# STM32F0x8 register map
File version: 1.3
CPU: CM0 r0p0, little endian, no MPU, no FPU, 2 interrupt priority bits
Registers are 32-bit, read-write, reset 0x0 unless marked. A register's access mark holds for its fields unless they carry their own. Offsets are from the block's base; [hi:lo] are bit positions; 'fields as' and 'values as' point back to an identical list.

## COMP — General purpose comparators
Base 0x40010000
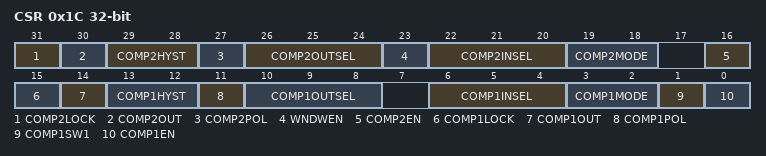
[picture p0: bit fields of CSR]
0x1C CSR access per field — control and status register
  [31] COMP2LOCK rw — Comparator 2 lock
    0=Unlocked (Comparator 2 CSR bits (CSR[31:16]) are read-write); 1=Locked (Comparator 2 CSR bits (CSR[31:16]) are read-only)
  [30] COMP2OUT ro — Comparator 2 output
    0=Low (Non-inverting input below inverting input); 1=High (Non-inverting input above inverting input)
  [29:28] COMP2HYST rw — Comparator 2 hysteresis
    0=NoHysteresis; 1=LowHysteresis; 2=MediumHysteresis; 3=HighHysteresis
  [27] COMP2POL rw — Comparator 2 output polarity
    0=NotInverted (Output is not inverted); 1=Inverted (Output is inverted)
  [26:24] COMP2OUTSEL rw — Comparator 2 output selection
    0=NoSelection; 1=Timer1BreakInput; 2=Timer1InputCapture1; 3=Timer1OCRefClearInput; 4=Timer2InputCapture4; 5=Timer2OCRefClearInput; 6=Timer3InputCapture1; 7=Timer3OCRefClearInput
  [23] WNDWEN rw — Window mode enable
    0=Disabled (Window mode disabled); 1=Enabled (Window mode enabled)
  [22:20] COMP2INSEL rw — Comparator 2 inverting input selection
    0=OneQuarterVRef (1/4 of VRefint); 1=OneHalfVRef (1/2 of VRefint); 2=ThreeQuarterVRef (3/4 of VRefint); 3=VRefint; 4=Comp2_INM4 (COMP1_INM4 (PA4 with DAC_OUT1 if enabled)); 5=Comp2_INM5 (COMP1_INM5 (PA5 with DAC_OUT2 if present and enabled)); 6=Comp2_INM6 (COMP1_INM6 (PA2))
  [19:18] COMP2MODE rw — Comparator 2 mode
    0=High speed / full power; 1=Medium speed / medium power; 2=Low speed / low power; 3=Very-low speed / ultra-low power
  [16] COMP2EN rw — Comparator 2 enable
    0=Disabled (Comparator 2 disabled); 1=Enabled (Comparator 2 enabled)
  [15] COMP1LOCK rw — Comparator 1 lock
    0=Unlocked (Comparator 1 CSR bits (CSR[15:0]) are read-write); 1=Locked (Comparator 1 CSR bits (CSR[15:0]) are read-only)
  [14] COMP1OUT ro — Comparator 1 output
    values as COMP2OUT
  [13:12] COMP1HYST rw — Comparator 1 hysteresis
    values as COMP2HYST
  [11] COMP1POL rw — Comparator 1 output polarity
    values as COMP2POL
  [10:8] COMP1OUTSEL rw — Comparator 1 output selection
    values as COMP2OUTSEL
  [6:4] COMP1INSEL rw — Comparator 1 inverting input selection
    0=OneQuarterVRef (1/4 of VRefint); 1=OneHalfVRef (1/2 of VRefint); 2=ThreeQuarterVRef (3/4 of VRefint); 3=VRefint; 4=COMP1_INM4 (PA4 with DAC_OUT1 if enabled); 5=COMP1_INM5 (PA5 with DAC_OUT2 if present and enabled); 6=COMP1_INM6 (PA0)
  [3:2] COMP1MODE rw — Comparator 1 mode
    values as COMP2MODE
  [1] COMP1SW1 rw — Comparator 1 non inverting input DAC switch
    0=Open (Switch open); 1=Closed (Switch closed)
  [0] COMP1EN rw — Comparator 1 enable
    0=Disabled (Comparator 1 disabled); 1=Enabled (Comparator 1 enabled)

## CEC — HDMI-CEC controller
Base 0x40007800
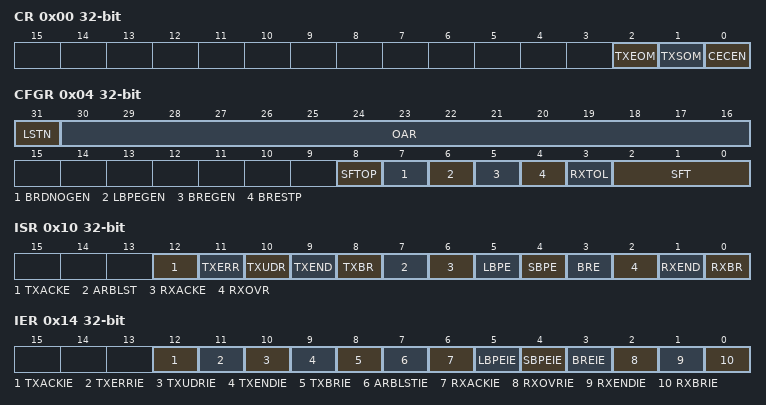
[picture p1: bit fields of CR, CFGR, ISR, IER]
0x00 CR — control register
  [2] TXEOM — Tx End Of Message
  [1] TXSOM — Tx start of message
  [0] CECEN — CEC Enable
0x04 CFGR — configuration register
  [31] LSTN — Listen mode
  [30:16] OAR — Own Address
  [8] SFTOP — SFT Option Bit
  [7] BRDNOGEN — Avoid Error-Bit Generation in Broadcast
  [6] LBPEGEN — Generate Error-Bit on Long Bit Period Error
  [5] BREGEN — Generate error-bit on bit rising error
  [4] BRESTP — Rx-stop on bit rising error
  [3] RXTOL — Rx-Tolerance
  [2:0] SFT — Signal Free Time
0x08 TXDR wo — Tx data register
  [7:0] TXD — Tx Data register
0x0C RXDR ro — Rx Data Register
  [7:0] RXDR — CEC Rx Data Register
0x10 ISR — Interrupt and Status Register
  [12] TXACKE — Tx-Missing acknowledge error
  [11] TXERR — Tx-Error
  [10] TXUDR — Tx-Buffer Underrun
  [9] TXEND — End of Transmission
  [8] TXBR — Tx-Byte Request
  [7] ARBLST — Arbitration Lost
  [6] RXACKE — Rx-Missing Acknowledge
  [5] LBPE — Rx-Long Bit Period Error
  [4] SBPE — Rx-Short Bit period error
  [3] BRE — Rx-Bit rising error
  [2] RXOVR — Rx-Overrun
  [1] RXEND — End Of Reception
  [0] RXBR — Rx-Byte Received
0x14 IER — interrupt enable register
  [12] TXACKIE — Tx-Missing Acknowledge Error Interrupt Enable
  [11] TXERRIE — Tx-Error Interrupt Enable
  [10] TXUDRIE — Tx-Underrun interrupt enable
  [9] TXENDIE — Tx-End of message interrupt enable
  [8] TXBRIE — Tx-Byte Request Interrupt Enable
  [7] ARBLSTIE — Arbitration Lost Interrupt Enable
  [6] RXACKIE — Rx-Missing Acknowledge Error Interrupt Enable
  [5] LBPEIE — Long Bit Period Error Interrupt Enable
  [4] SBPEIE — Short Bit Period Error Interrupt Enable
  [3] BREIE — Bit Rising Error Interrupt Enable
  [2] RXOVRIE — Rx-Buffer Overrun Interrupt Enable
  [1] RXENDIE — End Of Reception Interrupt Enable
  [0] RXBRIE — Rx-Byte Received Interrupt Enable
